# NUC100BN_v1 register map
File version: 1.0
Registers are 32-bit, read-write, reset 0x0 unless marked. A register's access mark holds for its fields unless they carry their own. Offsets are from the block's base; [hi:lo] are bit positions; lines under a group give offsets from that group; {n}, {i} and the like mark numbered series; 'fields as' and 'values as' point back to an identical list.

## PWMA — PWM Register Map
Base 0x40040000
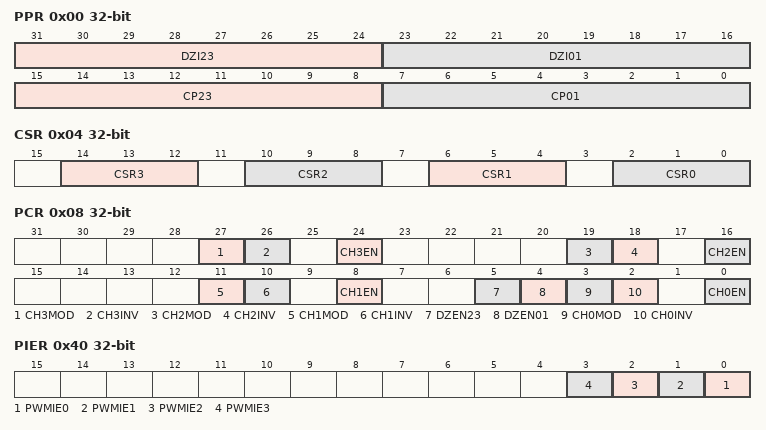
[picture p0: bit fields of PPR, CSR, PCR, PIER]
0x00 PPR — PWM Group A Prescaler Register. PWM Group B Prescaler Register (NuMicro( NUC100/NUC120 Medium Density Only)
  [31:24] DZI23 — Dead-zone Interval for Pair of Channel2 and Channel3 (PWM2 and PWM3 pair for PWM group A, PWM6 and PWM7 pair for PWM group B). These 8-bit determine the dead-zone length. The unit time of dead-zone length is received from corresponding CSR bits.
  [23:16] DZI01 — Dead-zone Interval for Pair of Channel 0 and Channel 1 (PWM0 and PWM1 Pair for PWM group A, PWM4 and PWM5 pair for PWM group B). These 8-bit determine the dead-zone length. The unit time of dead-zone length is received from corresponding CSR bits.
  [15:8] CP23 — Clock Prescaler 2 (PWM-timer2 /3 for group A and PWM-timer 6 / 7 for Group B). Clock input is divided by (CP23 + 1) before it is fed to the corresponding PWM-timer
  [7:0] CP01 — Clock Prescaler 0 (PWM-timer 0 / 1 for group A and PWM-timer 4 / 5 for Group B). Clock input is divided by (CP01 + 1) before it is fed to the corresponding PWM-timer
0x04 CSR — PWM Group A Clock Source Divider Select Register. PWM Group B Clock Source Divider Select Register (NuMicro( NUC100/NUC120 Medium Density Only)
  [14:12] CSR3 — PWM Timer 3 Clock Source Divider Selection (PWM timer 3 for group A and PWM timer 7 for group B)
  [10:8] CSR2 — PWM Timer 2 Clock Source Divider Selection (PWM timer 2 for group A and PWM timer 6 for group B). Select clock source divider for PWM timer 2. (Table is the same as CSR3.)
  [6:4] CSR1 — PWM Timer 1 Clock Source Divider Selection (PWM timer 1 for group A and PWM timer 5 for group B). Select clock source divider for PWM timer 1. (Table is the same as CSR3.)
  [2:0] CSR0 — PWM Timer 0 Clock Source Divider Selection (PWM timer 0 for group A and PWM timer 4 for group B). Select clock source divider for PWM timer 0. (Table is the same as CSR3.)
0x08 PCR — PWM Group A Control Register. PWM Group B Control Register (NuMicro( NUC100/NUC120 Medium Density Only)
  [27] CH3MOD — PWM-Timer 3 Auto-reload/One-Shot Mode (PWM timer 3 for group A and PWM timer 7 for group B). Note: If there is a transition at this bit, it will cause CNR3 and CMR3 be cleared.
    0=One-shot mode; 1=Auto-reload mode
  [26] CH3INV — PWM-Timer 3 Output Inverter Enable (PWM timer 3 for group A and PWM timer 7 for group B)
    0=Inverter Disabled; 1=Inverter Enabled
  [24] CH3EN — PWM-Timer 3 Enable (PWM timer 3 for group A and PWM timer 7 for group B)
    0=Corresponding PWM-Timer Running Stopped; 1=Corresponding PWM-Timer Start Run Enabled
  [19] CH2MOD — PWM-Timer 2 Auto-reload/One-Shot Mode (PWM timer 2 for group A and PWM timer 6 for group B). Note: If there is a transition at this bit, it will cause CNR2 and CMR2 be cleared.
    0=One-shot mode; 1=Auto-reload mode
  [18] CH2INV — PWM-Timer 2 Output Inverter Enable (PWM timer 2 for group A and PWM timer 6 for group B)
    0=Inverter Disabled; 1=Inverter Enabled
  [16] CH2EN — PWM-Timer 2 Enable (PWM timer 2 for group A and PWM timer 6 for Group B)
    0=corresponding PWM-Timer Running Stopped; 1=corresponding PWM-Timer Start Run Enabled
  [11] CH1MOD — PWM-Timer 1 Auto-reload/One-Shot Mode (PWM timer 1 for Group A and PWM timer 5 for Group B). Note: If there is a transition at this bit, it will cause CNR1 and CMR1 be cleared.
    0=One-shot mode; 1=Auto-load mode
  [10] CH1INV — PWM-Timer 1 Output Inverter Enable (PWM Timer 1 for Group A and PWM Timer 5 for Group B)
    0=Inverter Disabled; 1=Inverter Enabled
  [8] CH1EN — PWM-Timer 1 Enable (PWM Timer 1 for Group A and PWM Timer 5 for Group B)
    values as CH3EN
  [5] DZEN23 — Dead-Zone 2 Generator Enable (PWM2 and PWM3 Pair for PWM Group A, PWM6 and PWM7 Pair for PWM Group B). Note: When the Dead-Zone Generator is enabled, the pair of PWM2 and PWM3 becomes a complementary pair for PWM group A and the pair of PWM6 and PWM7 becomes a complementary pair for PWM group B.
    0=Disabled; 1=Enabled
  [4] DZEN01 — Dead-Zone 0 Generator Enable (PWM0 and PWM1 Pair for PWM Group A, PWM4 and PWM5 Pair for PWM Group B). Note: When Dead-Zone Generator is enabled, the pair of PWM0 and PWM1 becomes a complementary pair for PWM group A and the pair of PWM4 and PWM5 becomes a complementary pair for PWM group B.
    0=Disabled; 1=Enabled
  [3] CH0MOD — PWM-Timer 0 Auto-reload/One-Shot Mode (PWM Timer 0 for Group A and PWM Timer 4 for Group B). Note: If there is a transition at this bit, it will cause CNR0 and CMR0 be cleared.
    0=One-shot mode; 1=Auto-reload mode
  [2] CH0INV — PWM-Timer 0 Output Inverter Enable (PWM timer 0 for group A and PWM timer 4 for group B)
    0=Inverter Disabled; 1=Inverter Enabled
  [0] CH0EN — PWM-Timer 0 Enable (PWM timer 0 for group A and PWM timer 4 for group B)
    values as CH3EN
{0xC+0xC*i} CNR{i} (i=0..3) — PWM Group A Counter Register {i}. PWM Group B Counter Register {i} (NuMicro( NUC100/NUC120 Medium Density Only)
  [15:0] CNRx — PWM Timer Loaded Value. CNR determines the PWM period. Note: Any write to CNR will take effect in next PWM cycle.
{0x10+0xC*i} CMR{i} (i=0..3) — PWM Group A Comparator Register {i}. PWM Group B Comparator Register {i} (NuMicro( NUC100/NUC120 Medium Density Only)
  [15:0] CMRx — PWM Comparator Register. CMR determines the PWM duty. Note: Any write to CMR will take effect in next PWM cycle.
{0x14+0xC*i} PDR{i} ro (i=0..3) — PWM Group A Data Register {i}. PWM Group B Data Register {i} (NuMicro( NUC100/NUC120 Medium Density Only)
  [15:0] PDRx — PWM Data Register. User can monitor PDR to know the current value in 16-bit down counter.
0x3C PBCR — PWM Backward Compatible Register (NuMicro( NUC100/NUC120 Low Density Only)
  [0] BCn — PWM Backward Compatible Register. Refer to the CCR0/CCR2 register bit 6, 7, 22, 23 descriptions.
    0=Configure write 0 to clear CFLRI0~3 and CRLRI0~3; 1=Configure write 1 to clear CFLRI0~3 and CRLRI0~3
0x40 PIER — PWM Group A Interrupt Enable Register. PWM Group B Interrupt Enable Register (NuMicro( NUC100/NUC120 Medium Density Only)
  [all] fields
    0=Disabled; 1=Enabled
  [n] PWMIE{n} (n=0..3) — PWM channel {n} Interrupt Enable
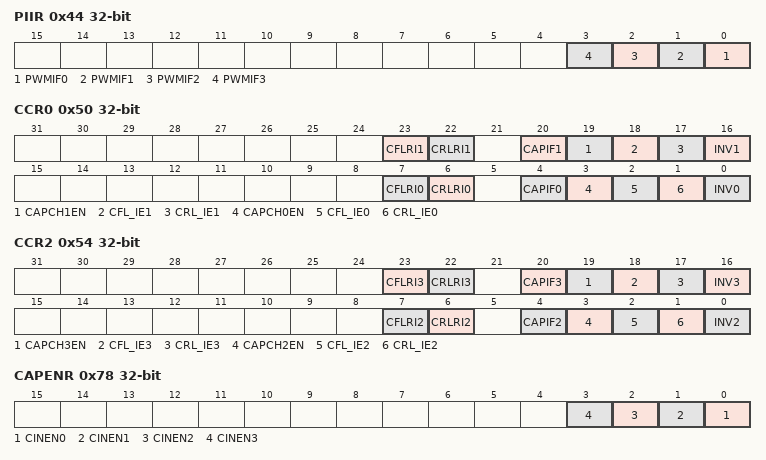
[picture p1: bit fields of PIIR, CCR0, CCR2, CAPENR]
0x44 PIIR — PWM Group A Interrupt Indication Register. PWM Group B Interrupt Indication Register (NuMicro( NUC100/NUC120 Medium Density Only)
  [n] PWMIF{n} (n=0..3) — PWM channel {n} Interrupt Status. This bit is set by hardware when PWM{n} down counter reaches zero if PWM3 interrupt enable bit (PWMIE{n}) is 1, software can write 1 to clear this bit to zero
0x50 CCR0 — PWM Group A Capture Control Register 0. PWM Group B Capture Control Register 0 (NuMicro( NUC100/NUC120 Medium Density Only)
  [23] CFLRI1 — CFLR1 Latched Indicator Bit. When PWM group input channel 1 has a falling transition, CFLR1 was latched with the value of PWM down-counter and this bit is set by hardware. In NuMicro( NUC100/NUC120 Medium Density, software can write 0 to clear this bit to zero. In NuMicro( NUC100/NUC120 Low Density, software can write 0 to clear this bit to zero if BCn bit is 0, and can Write 1 to clear this bit to zero if BCn bit is 1.
  [22] CRLRI1 — CRLR1 Latched Indicator Bit. When PWM group input channel 1 has a rising transition, CRLR1 was latched with the value of PWM down-counter and this bit is set by hardware. In NuMicro( NUC100/NUC120 Medium Density, software can write 0 to clear this bit to zero. In NuMicro( NUC100/NUC120 Low Density, software can write 0 to clear this bit to zero if BCn bit is 0, and can Write 1 to clear this bit to zero if BCn bit is 1.
  [20] CAPIF1 — Channel 1 Capture Interrupt Indication Flag. Write 1 to clear this bit to zero
  [19] CAPCH1EN — Channel 1 Capture Function Enable. When Enabled, Capture latched the PWM-counter and saved to CRLR (Rising latch) and CFLR (Falling latch). When Disabled, Capture does not update CRLR and CFLR, and disable PWM group channel 1 Interrupt.
    0=Capture function on PWM group channel 1 Disabled; 1=Capture function on PWM group channel 1 Enabled
  [18] CFL_IE1 — Channel 1 Falling Latch Interrupt Enable. When Enabled, if Capture detects PWM group channel 1 has falling transition, Capture will issue an Interrupt.
    0=Falling latch interrupt Disabled; 1=Falling latch interrupt Enabled
  [17] CRL_IE1 — Channel 1 Rising Latch Interrupt Enable. When Enabled, if Capture detects PWM group channel 1 has rising transition, Capture will issue an Interrupt.
    0=Rising latch interrupt Disabled; 1=Rising latch interrupt Enabled
  [16] INV1 — Channel 1 Inverter Enable
    0=Inverter Disabled; 1=Inverter Enabled. Reverse the input signal from GPIO before fed to Capture timer
  [7] CFLRI0 — CFLR0 Latched Indicator Bit. When PWM group input channel 0 has a falling transition, CFLR0 was latched with the value of PWM down-counter and this bit is set by hardware. In NuMicro( NUC100/NUC120 Medium Density, software can write 0 to clear this bit to zero. In NuMicro( NUC100/NUC120 Low Density, software can write 0 to clear this bit to zero if BCn bit is 0, and can Write 1 to clear this bit to zero if BCn bit is 1.
  [6] CRLRI0 — CRLR0 Latched Indicator Bit. When PWM group input channel 0 has a rising transition, CRLR0 was latched with the value of PWM down-counter and this bit is set by hardware. In NuMicro( NUC100/NUC120 Medium Density, software can write 0 to clear this bit to zero. In NuMicro( NUC100/NUC120 Low Density, software can write 0 to clear this bit to zero if BCn bit is 0, and can Write 1 to clear this bit to zero if BCn bit is 1.
  [4] CAPIF0 — Channel 0 Capture Interrupt Indication Flag. Write 1 to clear this bit to zero
  [3] CAPCH0EN — Channel 0 Capture Function Enable. When Enabled, Capture latched the PWM-counter value and saved to CRLR (Rising latch) and CFLR (Falling latch). When Disabled, Capture does not update CRLR and CFLR, and disable PWM group channel 0 Interrupt.
    0=Capture function on PWM group channel 0 Disabled; 1=Capture function on PWM group channel 0 Enabled
  [2] CFL_IE0 — Channel 0 Falling Latch Interrupt Enable. When Enabled, if Capture detects PWM group channel 0 has falling transition, Capture will issue an Interrupt.
    values as CFL_IE1
  [1] CRL_IE0 — Channel 0 Rising Latch Interrupt Enable. When Enabled, if Capture detects PWM group channel 0 has rising transition, Capture will issue an Interrupt.
    values as CRL_IE1
  [0] INV0 — Channel 0 Inverter Enable
    values as INV1
0x54 CCR2 — PWM Group A Capture Control Register 2. PWM Group B Capture Control Register 2 (NuMicro( NUC100/NUC120 Medium Density Only)
  [23] CFLRI3 — CFLR3 Latched Indicator Bit. When PWM group input channel 3 has a falling transition, CFLR3 was latched with the value of PWM down-counter and this bit is set by hardware. In NuMicro( NUC100/NUC120 Medium Density, software can write 0 to clear this bit to zero. In NuMicro( NUC100/NUC120 Low Density, software can write 0 to clear this bit to zero if BCn bit is 0, and can Write 1 to clear this bit to zero if BCn bit is 1.
  [22] CRLRI3 — CRLR3 Latched Indicator Bit. When PWM group input channel 3 has a rising transition, CRLR3 was latched with the value of PWM down-counter and this bit is set by hardware. In NuMicro( NUC100/NUC120 Medium Density, software can write 0 to clear this bit to zero. In NuMicro( NUC100/NUC120 Low Density, software can write 0 to clear this bit to zero if BCn bit is 0, and can write 1 to clear this bit to zero if BCn bit is 1.
  [20] CAPIF3 — Channel 3 Capture Interrupt Indication Flag. Write 1 to clear this bit to 0.
  [19] CAPCH3EN — Channel 3 Capture Function Enable. When Enabled, Capture latched the PWM-counter and saved to CRLR (Rising latch) and CFLR (Falling latch). When Disabled, Capture does not update CRLR and CFLR, and disable PWM group channel 3 Interrupt.
    0=Capture function on PWM group channel 3 Disabled; 1=Capture function on PWM group channel 3 Enabled
  [18] CFL_IE3 — Channel 3 Falling Latch Interrupt Enable. When Enabled, if Capture detects PWM group channel 3 has falling transition, Capture will issue an Interrupt.
    values as CCR0.CFL_IE1
  [17] CRL_IE3 — Channel 3 Rising Latch Interrupt Enable. When Enabled, if Capture detects PWM group channel 3 has rising transition, Capture will issue an Interrupt.
    values as CCR0.CRL_IE1
  [16] INV3 — Channel 3 Inverter Enable
    values as CCR0.INV1
  [7] CFLRI2 — CFLR2 Latched Indicator Bit. When PWM group input channel 2 has a falling transition, CFLR2 was latched with the value of PWM down-counter and this bit is set by hardware. In NuMicro( NUC100/NUC120 Medium Density, software can write 0 to clear this bit to zero. In NuMicro( NUC100/NUC120 Low Density, software can write 0 to clear this bit to zero if BCn bit is 0, and can Write 1 to clear this bit to zero if BCn bit is 1.
  [6] CRLRI2 — CRLR2 Latched Indicator Bit. When PWM group input channel 2 has a rising transition, CRLR2 was latched with the value of PWM down-counter and this bit is set by hardware. In NuMicro( NUC100/NUC120 Medium Density, software can write 0 to clear this bit to zero. In NuMicro( NUC100/NUC120 Low Density, software can write 0 to clear this bit to zero if BCn bit is 0, and can Write 1 to clear this bit to zero if BCn bit is 1.
  [4] CAPIF2 — Channel 2 Capture Interrupt Indication Flag. Write 1 to clear this bit to zero
  [3] CAPCH2EN — Channel 2 Capture Function Enable. When Enabled, Capture latched the PWM-counter value and saved to CRLR (Rising latch) and CFLR (Falling latch). When Disabled, Capture does not update CRLR and CFLR, and disable PWM group channel 2 Interrupt.
    0=Capture function on PWM group channel 2 Disabled; 1=Capture function on PWM group channel 2 Enabled
  [2] CFL_IE2 — Channel 2 Falling Latch Interrupt Enable. When Enabled, if Capture detects PWM group channel 2 has falling transition, Capture will issue an Interrupt.
    values as CCR0.CFL_IE1
  [1] CRL_IE2 — Channel 2 Rising Latch Interrupt Enable. When Enabled, if Capture detects PWM group channel 2 has rising transition, Capture will issue an Interrupt.
    values as CCR0.CRL_IE1
  [0] INV2 — Channel 2 Inverter Enable
    values as CCR0.INV1
{0x58+8i} CRLR{i} ro (i=0..3) — PWM Group A Capture Rising Latch Register (Channel {i}). PWM Group B Capture Rising Latch Register (Channel {i}) (NuMicro( NUC100/NUC120 Medium Density Only)
  [15:0] CRLRx — Capture Rising Latch Register. Latch the PWM counter when Channel 0/1/2/3 has rising transition.
{0x5C+8i} CFLR{i} ro (i=0..3) — PWM Group A Capture Falling Latch Register (Channel {i}). PWM Group B Capture Falling Latch Register (Channel {i}) (NuMicro( NUC100/NUC120 Medium Density Only)
  [15:0] CFLRx — Capture Falling Latch Register. Latch the PWM counter when Channel 0/1/2/3 has Falling transition.
0x78 CAPENR — PWM Group A Capture Input 0~3 Enable Register. PWM Group B Capture Input 0~3 Enable Register (NuMicro( NUC100/NUC120 Medium Density Only)
  [n] CINEN{n} (n=0..3) — Channel {n} Capture Input Enable
    0=PWM Channel {n} capture input path Disabled. The input of PWM channel {n} capture function is always regarded as 0; 1=PWM Channel {n} capture input path Enabled. The input of PWM channel {n} capture function comes from correlative multifunction pin if GPIO multi-function is set as PWM{n}
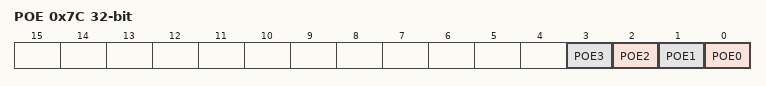
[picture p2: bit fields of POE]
0x7C POE — PWM Group A Output Enable for Channel 0~3. PWM Group B Output Enable for Channel 0~3 (NuMicro( NUC100/NUC120 Medium Density Only)
  [n] POE{n} (n=0..3) — Channel {n} Output Enable Register. Note: The corresponding GPIO pin must also be switched to PWM function.
    0=PWM channel {n} output to pin Disabled; 1=PWM channel {n} output to pin Enabled

## PWMB — PWM Register Map
Base 0x40140000
Registers as PWMA, without PBCR.
